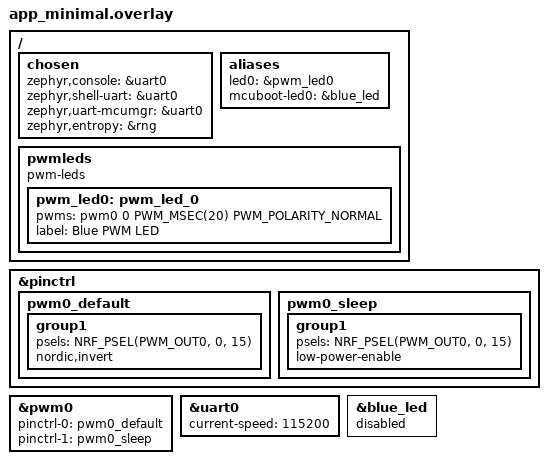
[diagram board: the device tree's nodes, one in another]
/*
 * Minimal overlay for testing bootloader compatibility
 * Just defines the Blue LED - no complex peripherals
 */

#include <zephyr/dt-bindings/pwm/pwm.h>

/ {
	chosen {
		zephyr,console = &uart0;
		zephyr,shell-uart = &uart0;
		zephyr,uart-mcumgr = &uart0;
		zephyr,entropy = &rng;
	};

	aliases {
		led0 = &pwm_led0;
		mcuboot-led0 = &blue_led;
	};

	pwmleds {
		compatible = "pwm-leds";
		pwm_led0: pwm_led_0 {
			pwms = <&pwm0 0 PWM_MSEC(20) PWM_POLARITY_NORMAL>;
			label = "Blue PWM LED";
		};
	};
};

/* Configure PWM0 for the Blue LED on P0.15 */
&pinctrl {
	pwm0_default: pwm0_default {
		group1 {
			psels = <NRF_PSEL(PWM_OUT0, 0, 15)>;
			nordic,invert;
		};
	};

	pwm0_sleep: pwm0_sleep {
		group1 {
			psels = <NRF_PSEL(PWM_OUT0, 0, 15)>;
			low-power-enable;
		};
	};
};

&pwm0 {
	status = "okay";
	pinctrl-0 = <&pwm0_default>;
	pinctrl-1 = <&pwm0_sleep>;
	pinctrl-names = "default", "sleep";
};

/* Keep UART for console output */
&uart0 {
	status = "okay";
	current-speed = <115200>;
};

/* Disable the original GPIO LED to avoid conflict */
&blue_led {
	status = "disabled";
};
